# STM32L412C8T6 register map
File version: 1.0
Registers are 32-bit, access not given, reset 0x0 unless marked. A register's access mark holds for its fields unless they carry their own. Offsets are from the block's base; [hi:lo] are bit positions; {n}, {i} and the like mark numbered series.

## USBFS
Base 0x40006800
Same registers: USBSRAM 0x40006C00
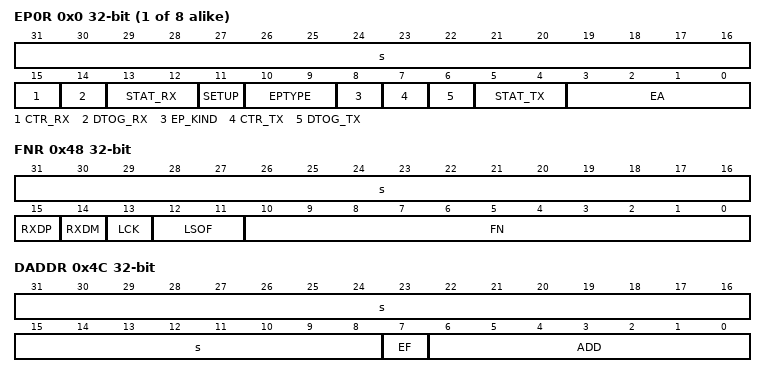
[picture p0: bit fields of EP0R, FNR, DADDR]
{0x0+4i} EP{i}R (i=0..7)
  [31:16] s, [15] CTR_RX, [14] DTOG_RX, [13:12] STAT_RX, [11] SETUP, [10:9] EPTYPE, [8] EP_KIND, [7] CTR_TX, [6] DTOG_TX, [5:4] STAT_TX, [3:0] EA
0x40 CNTR
  [15] CTRM, [14] PMAOVRM, [13] ERRM, [12] WKUPM, [11] SUSPM, [10] RESETM, [9] SOFM, [8] ESOFM, [7] L1REQM, [31:6] s, [5] L1RESUME, [4] RESUME, [3] FSUSP, [2] LP_MODE, [1] PDWN, [0] FRES
0x44 ISTR
  [15] CTR, [14] PMAOVR, [13] ERR, [12] WKUP, [11] SUSP, [10] RESET, [9] SOF, [8] ESOF, [7] L1REQ, [31:5] s, [4] DIR, [3:0] EP_ID
0x48 FNR
  [31:16] s, [15] RXDP, [14] RXDM, [13] LCK, [12:11] LSOF, [10:0] FN
0x4C DADDR
  [31:8] s, [7] EF, [6:0] ADD
0x50 BTABLE
  [15:3] BTABLE, [31:0] s
0x54 LPMCSR
  [7:4] BESL, [3] REMWAKE, [31:2] s, [1] LPMACK, [0] LPMEN
0x58 BCDR
  [15] DPPU, [31:8] s, [7] PS2DET, [6] SDET, [5] PDET, [4] DCDET, [3] SDEN, [2] PDEN, [1] DCDEN, [0] BCDEN

## PWR
Base 0x40007000
0x00 CR1
  [14] LPR, [10:9] VOS, [8] DBP, [31:3] s, [2:0] LPMS
0x04 CR2
  [10] USV, [7] PVME4, [6] PVME3, [31:5] s, [4] PVME1, [3:1] PLS, [0] PVDE
0x08 CR3
  [15] EIWUL, [11] ENULP, [10] APC, [8] RRS, [31:5] s, [n-1] EWUP{n} (n=1..5)
0x0C CR4
  [9] VBRS, [8] VBE, [31:5] s, [n-1] WP{n} (n=1..5)
0x10 SR1
  [15] WUFI, [8] SBF, [31:5] s, [n-1] WUF{n} (n=1..5)
0x14 SR2
  [15] PVMO4, [14] PVMO3, [12] PVMO1, [11] PVDO, [10] VOSF, [9] REGLPF, [8] REGLPS, [31:0] s
0x18 SCR
  [8] CSBF, [31:5] s, [n-1] CWUF{n} (n=1..5)
0x20 PUCRA
  [15] PU15, [31:14] s, [n] PU{n} (n=0..13)
0x24 PDCRA
  [14] PD14, [31:13] s, [n] PD{n} (n=0..12)
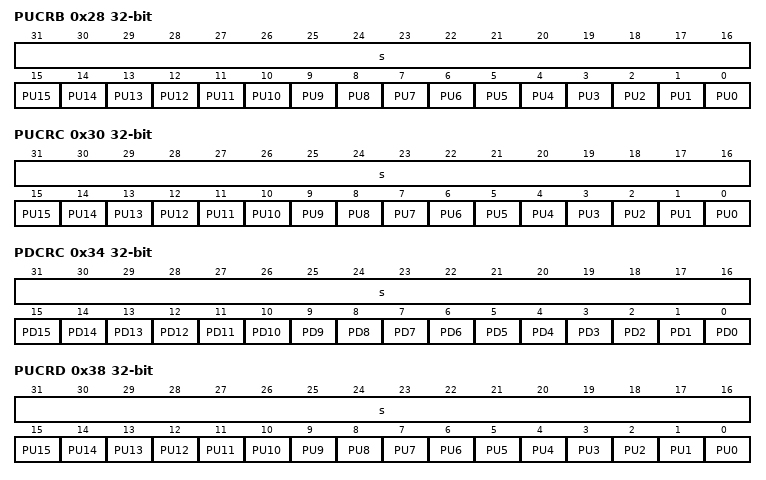
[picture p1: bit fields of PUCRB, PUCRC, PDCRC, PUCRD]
0x28 PUCRB
  [31:16] s, [n] PU{n} (n=0..15)
0x2C PDCRB
  [n] PD{n} (n=5..15), [31:4] s, [n] PD{n} (n=0..3)
0x30 PUCRC
  [31:16] s, [n] PU{n} (n=0..15)
0x34 PDCRC
  [31:16] s, [n] PD{n} (n=0..15)
0x38 PUCRD
  [31:16] s, [n] PU{n} (n=0..15)
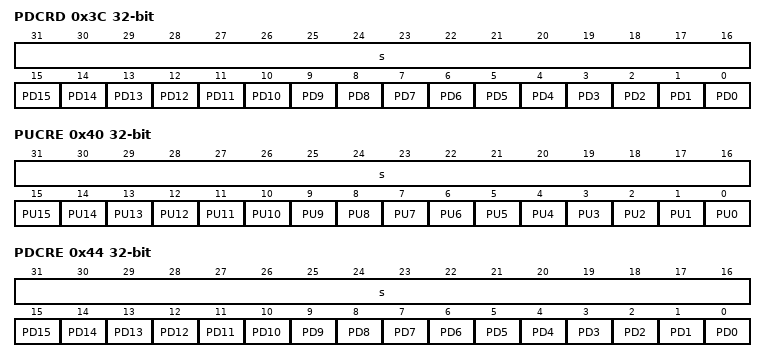
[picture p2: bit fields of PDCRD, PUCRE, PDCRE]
0x3C PDCRD
  [31:16] s, [n] PD{n} (n=0..15)
0x40 PUCRE
  [31:16] s, [n] PU{n} (n=0..15)
0x44 PDCRE
  [31:16] s, [n] PD{n} (n=0..15)
0x58 PUCRH
  [3] PU3, [31:2] s, [1] PU1, [0] PU0
0x5C PDCRH
  [3] PD3, [31:2] s, [1] PD1, [0] PD0

## DAC1
Base 0x40007400
0x00 CR
  [30] CEN2, [29] DMAUDRIE2, [28] DMAEN2, [27:24] MAMP2, [23:22] WAVE2, [21] TSEL22, [20] TSEL21, [19] TSEL20, [18] TEN2, [16] EN2, [14] CEN1, [13] DMAUDRIE1, [12] DMAEN1, [11:8] MAMP1, [7:6] WAVE1, [5] TSEL12, [4] TSEL11, [3] TSEL10, [2] TEN1, [31:1] s, [0] EN1
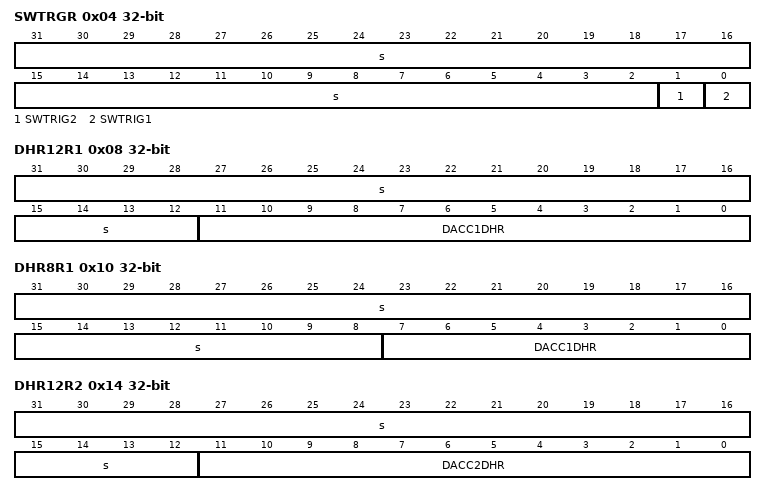
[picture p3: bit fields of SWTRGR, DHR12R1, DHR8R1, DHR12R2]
0x04 SWTRGR
  [31:2] s, [1] SWTRIG2, [0] SWTRIG1
0x08 DHR12R1
  [31:12] s, [11:0] DACC1DHR
0x0C DHR12L1
  [15:4] DACC1DHR, [31:0] s
0x10 DHR8R1
  [31:8] s, [7:0] DACC1DHR
0x14 DHR12R2
  [31:12] s, [11:0] DACC2DHR
0x18 DHR12L2
  [15:4] DACC2DHR, [31:0] s
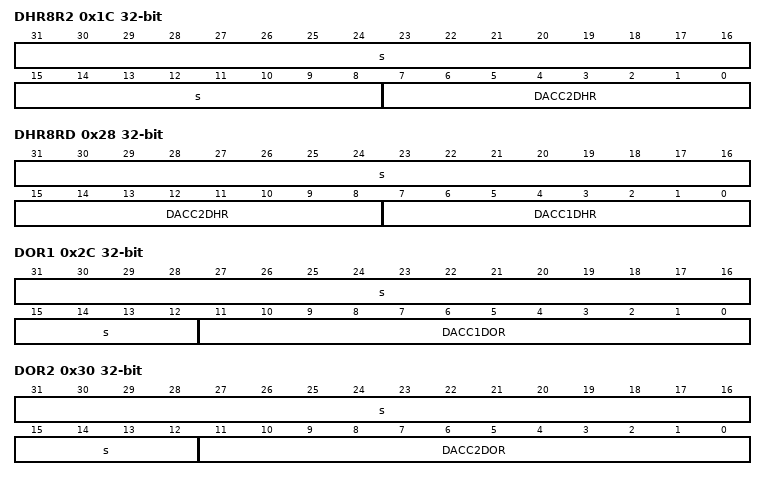
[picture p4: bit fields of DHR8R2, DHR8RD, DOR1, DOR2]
0x1C DHR8R2
  [31:8] s, [7:0] DACC2DHR
0x20 DHR12RD
  [27:16] DACC2DHR, [31:12] s, [11:0] DACC1DHR
0x24 DHR12LD
  [31:20] DACC2DHR, [15:4] DACC1DHR, [19:0] s
0x28 DHR8RD
  [31:16] s, [15:8] DACC2DHR, [7:0] DACC1DHR
0x2C DOR1
  [31:12] s, [11:0] DACC1DOR
0x30 DOR2
  [31:12] s, [11:0] DACC2DOR
0x34 SR
  [31] BWST2, [30] CAL_FLAG2, [29] DMAUDR2, [15] BWST1, [14] CAL_FLAG1, [13] DMAUDR1, [28:0] s
0x38 CCR
  [20:16] OTRIM2, [31:5] s, [4:0] OTRIM1
0x3C MCR
  [18:16] MODE2, [31:3] s, [2:0] MODE1
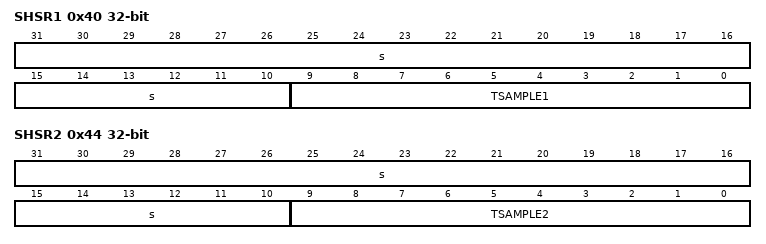
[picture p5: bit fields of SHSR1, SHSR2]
0x40 SHSR1
  [31:10] s, [9:0] TSAMPLE1
0x44 SHSR2
  [31:10] s, [9:0] TSAMPLE2
0x48 SHHR
  [25:16] THOLD2, [31:10] s, [9:0] THOLD1
0x4C SHRR
  [23:16] TREFRESH2, [31:8] s, [7:0] TREFRESH1

## OPAMP
Base 0x40007800
0x00 OPAMP1_CSR
  [31] OPA_RANGE, [15] CALOUT, [14] USERTRIM, [13] CALSEL, [12] CALON, [10] VP_SEL, [9:8] VM_SEL, [30:6] s, [5:4] PGA_GAIN, [3:2] OPAMODE, [1] OPALPM, [0] OPAEN
0x04 OPAMP1_OTR
  [12:8] TRIMOFFSETP, [31:5] s, [4:0] TRIMOFFSETN
0x08 OPAMP1_LPOTR
  [12:8] TRIMLPOFFSETP, [31:5] s, [4:0] TRIMLPOFFSETN

## LPTIM1
Base 0x40007C00
Same registers: TIM1 0x40012C00
0x00 CR1
  [11] UIFREMAP, [31:10] s, [9:8] CKD, [7] ARPE, [6:5] CMS, [4] DIR, [3] OPM, [2] URS, [1] UDIS, [0] CEN
0x04 CR2
  [23:20] MMS2, [2n+6] OIS{n} (n=1..6), [13] OIS3N, [11] OIS2N, [9] OIS1N, [7] TI1S, [6:4] MMS, [3] CCDS, [2] CCUS, [31:1] s, [0] CCPC
0x08 SMCR
  [31:17] s, [15] ETP, [14] ECE, [13:12] ETPS, [11:8] ETF, [7] MSM, [6:4] TS, [3] OCCS, [16:0] SMS
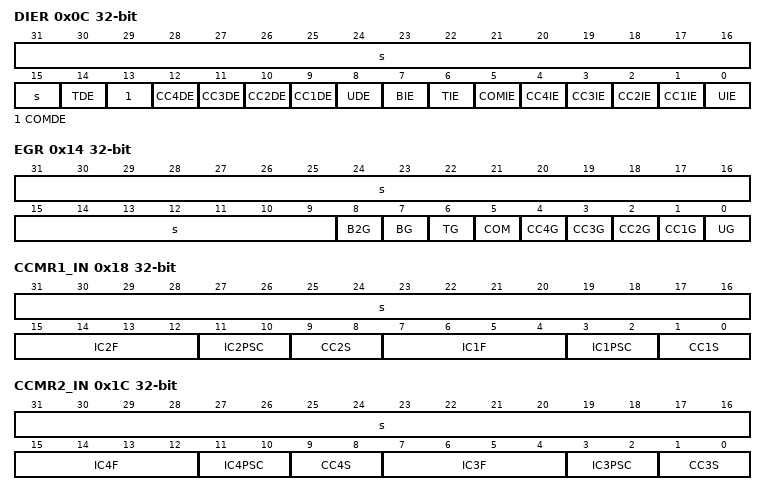
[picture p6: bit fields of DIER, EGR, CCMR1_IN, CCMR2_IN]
0x0C DIER
  [31:15] s, [14] TDE, [13] COMDE, [n+8] CC{n}DE (n=1..4), [8] UDE, [7] BIE, [6] TIE, [5] COMIE, [n] CC{n}IE (n=1..4), [0] UIE
0x10 SR
  [17] CC6IF, [16] CC5IF, [31:14] s, [13] SBIF, [n+8] CC{n}OF (n=1..4), [8] B2IF, [7] BIF, [6] TIF, [5] COMIF, [n] CC{n}IF (n=1..4), [0] UIF
0x14 EGR
  [31:9] s, [8] B2G, [7] BG, [6] TG, [5] COM, [n] CC{n}G (n=1..4), [0] UG
0x18 CCMR1_OUT
  [31:17] s, [15] OC2CE, [24:12] OC2M, [11] OC2PE, [10] OC2FE, [9:8] CC2S, [7] OC1CE, [16:4] OC1M, [3] OC1PE, [2] OC1FE, [1:0] CC1S
0x18 CCMR1_IN
  [31:16] s, [15:12] IC2F, [11:10] IC2PSC, [9:8] CC2S, [7:4] IC1F, [3:2] IC1PSC, [1:0] CC1S
0x1C CCMR2_OUT
  [31:17] s, [15] OC4CE, [24:12] OC4M, [11] OC4PE, [10] OC4FE, [9:8] CC4S, [7] OC3CE, [16:4] OC3M, [3] OC3PE, [2] OC3FE, [1:0] CC3S
0x1C CCMR2_IN
  [31:16] s, [15:12] IC4F, [11:10] IC4PSC, [9:8] CC4S, [7:4] IC3F, [3:2] IC3PSC, [1:0] CC3S
0x20 CCER
  [4n-3] CC{n}P (n=1..6), [4n-4] CC{n}E (n=1..6), [4n-1] CC{n}NP (n=1..4), [31:14] s, [10] CC3NE, [6] CC2NE, [2] CC1NE
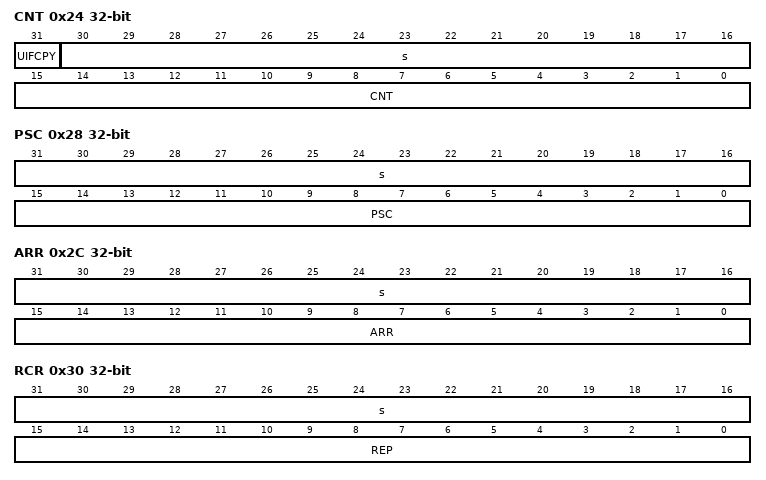
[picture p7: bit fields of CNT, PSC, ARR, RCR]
0x24 CNT
  [31] UIFCPY, [30:16] s, [15:0] CNT
0x28 PSC
  [31:16] s, [15:0] PSC
0x2C ARR
  [31:16] s, [15:0] ARR
0x30 RCR
  [31:16] s, [15:0] REP
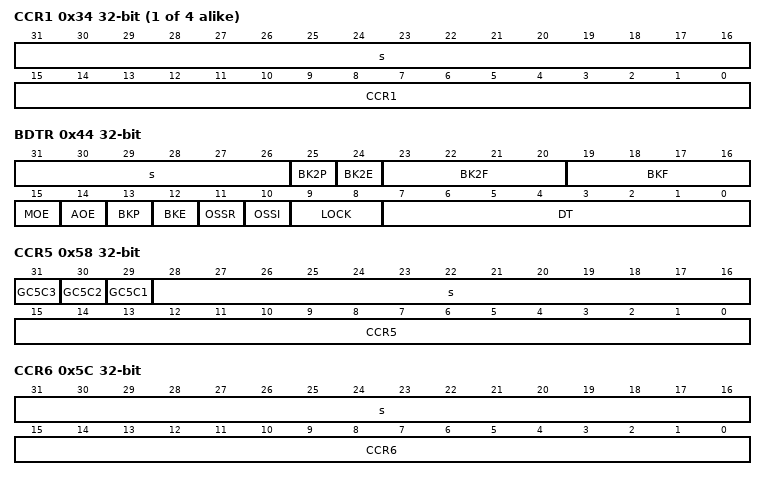
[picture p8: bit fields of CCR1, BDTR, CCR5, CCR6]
{0x30+4i} CCR{i} (i=1..4)
  [31:16] s, [15:0] CCR{i}
0x44 BDTR
  [31:26] s, [25] BK2P, [24] BK2E, [23:20] BK2F, [19:16] BKF, [15] MOE, [14] AOE, [13] BKP, [12] BKE, [11] OSSR, [10] OSSI, [9:8] LOCK, [7:0] DT
0x48 DCR
  [12:8] DBL, [31:5] s, [4:0] DBA
0x4C DMAR
  [31:0] DMAB
0x50 OR1
  [4] TI1_RMP, [31:2] s, [1:0] ETR_ADC1_RMP
0x54 CCMR3_OUT
  [15] OC6CE, [24:12] OC6M, [11] OC6PE, [10] OC6FE, [7] OC5CE, [16:4] OC5M, [3] OC5PE, [2] OC5FE, [31:0] s
0x58 CCR5
  [31] GC5C3, [30] GC5C2, [29] GC5C1, [28:16] s, [15:0] CCR5
0x5C CCR6
  [31:16] s, [15:0] CCR6
0x60 OR2
  [16:14] ETRSEL, [11] BKCMP2P, [10] BKCMP1P, [9] BKINP, [31:3] s, [2] BKCMP2E, [1] BKCMP1E, [0] BKINE
0x64 OR3
  [11] BK2CMP2P, [10] BK2CMP1P, [9] BK2INP, [31:3] s, [2] BK2CMP2E, [1] BK2CMP1E, [0] BK2INE
